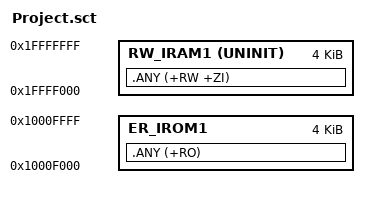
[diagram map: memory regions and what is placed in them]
; *************************************************************
; *** Scatter-Loading Description File generated by uVision ***
; *************************************************************

LR_IROM1 0x1000F000 0x00001000  {    ; load region size_region
  ER_IROM1 0x1000F000 0x00001000  {  ; load address = execution address
   .ANY (+RO)
  }
  RW_IRAM1 0x1FFFF000 UNINIT 0x00001000  {  ; RW data
   .ANY (+RW +ZI)
  }
}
